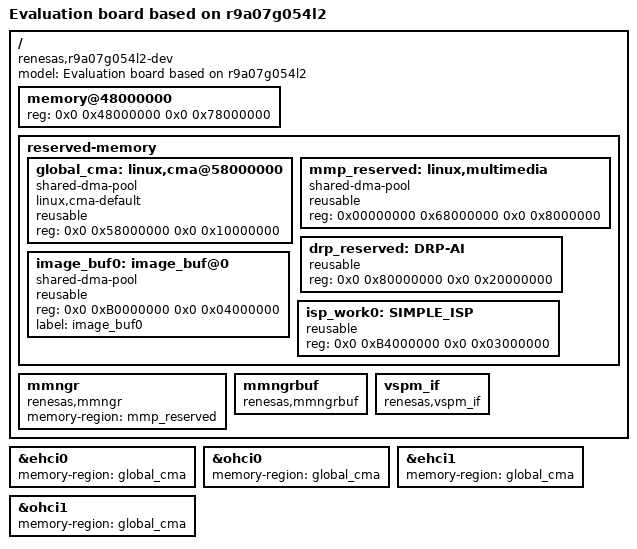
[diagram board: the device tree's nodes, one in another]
// SPDX-License-Identifier: GPL-2.0
/*
 * Device Tree Source for the RZV2L Dual A55 Evaluation board
 *
 * Copyright (C) 2022 Renesas Electronics Corp.
 */

/dts-v1/;
#include "r9a07g054l2.dtsi"
#include "rzg2l-smarc-dev.dtsi"

/ {
	model = "Evaluation board based on r9a07g054l2";
	compatible = "renesas,r9a07g054l2-dev", "renesas,r9a07g054l2";

	memory@48000000 {
		device_type = "memory";
		/* first 128MB is reserved for secure area. */
		reg = <0x0 0x48000000 0x0 0x78000000>;
	};

	reserved-memory {
		#address-cells = <2>;
		#size-cells = <2>;
		ranges;

		global_cma: linux,cma@58000000 {
			compatible = "shared-dma-pool";
			linux,cma-default;
			reusable;
			reg = <0x0 0x58000000 0x0 0x10000000>;
		};
		mmp_reserved: linux,multimedia {
			compatible = "shared-dma-pool";
			reusable;
			reg = <0x00000000 0x68000000 0x0 0x8000000>;
		};

		/* device specific region for contiguous allocations */
		drp_reserved: DRP-AI {
			reusable;
			reg = <0x0 0x80000000 0x0 0x20000000>;
		};

		image_buf0: image_buf@0 {
			compatible = "shared-dma-pool";
			reusable;
			reg = <0x0 0xB0000000 0x0 0x04000000>;
			label = "image_buf0";
		};

		isp_work0: SIMPLE_ISP {
			reusable;
			reg = <0x0 0xB4000000 0x0 0x03000000>;
		};
	};

	mmngr {
		compatible = "renesas,mmngr";
		memory-region = <&mmp_reserved>;
	};

	mmngrbuf {
		compatible = "renesas,mmngrbuf";
	};

	vspm_if {
		compatible = "renesas,vspm_if";
	};
};

&ehci0 {
	memory-region = <&global_cma>;
};

&ohci0 {
	memory-region = <&global_cma>;
};

&ehci1 {
	memory-region = <&global_cma>;
};

&ohci1 {
	memory-region = <&global_cma>;
};
